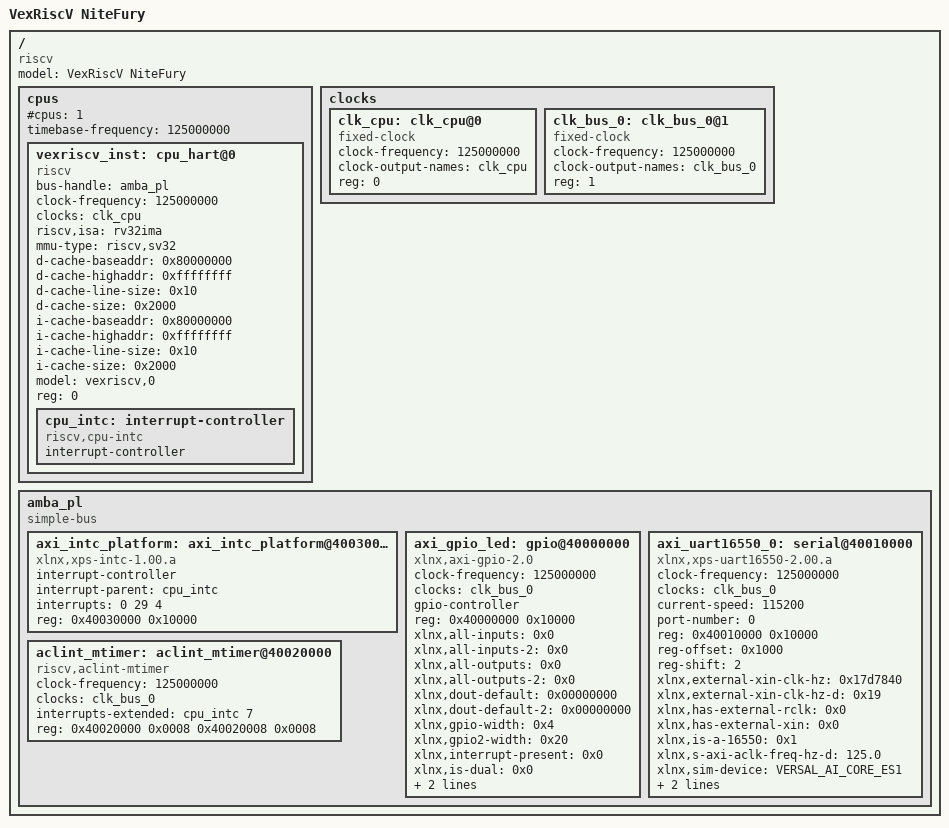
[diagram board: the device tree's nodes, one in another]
/*
 * CAUTION: This file is automatically generated by Xilinx.
 * Version: XSCT 2021.1
 * Today is: Sat Jan 15 06:48:48 2022
 */


/ {
	#address-cells = <1>;
	#size-cells = <1>;
	compatible = "riscv";
	model = "VexRiscV NiteFury";
	cpus {
		#address-cells = <1>;
		#cpus = <1>;
		#size-cells = <0>;
		timebase-frequency = <125000000>;

		vexriscv_inst: cpu_hart@0 {
			bus-handle = <&amba_pl>;
			clock-frequency = <125000000>;
			clocks = <&clk_cpu>;
			compatible = "riscv";
			riscv,isa = "rv32ima";
			mmu-type = "riscv,sv32";
			d-cache-baseaddr = <0x80000000>;
			d-cache-highaddr = <0xffffffff>;
			d-cache-line-size = <0x10>;
			d-cache-size = <0x2000>;
			device_type = "cpu";
			i-cache-baseaddr = <0x80000000>;
			i-cache-highaddr = <0xffffffff>;
			i-cache-line-size = <0x10>;
			i-cache-size = <0x2000>;
			//interrupt-handle = <&axi_intc_platform>;
			model = "vexriscv,0";
			reg = <0>;
			status = "okay";
			cpu_intc: interrupt-controller {
				compatible = "riscv,cpu-intc";
				#interrupt-cells = <1>;
				interrupt-controller;
			};
			// cpu_cycle_timer: cycle_timer {
			// 	clock-frequency = <125000000>;
			// 	compatible = "riscv,cycle-timer";
			// };
		};
	};
	clocks {
		#address-cells = <1>;
		#size-cells = <0>;
		clk_cpu: clk_cpu@0 {
			#clock-cells = <0>;
			clock-frequency = <125000000>;
			clock-output-names = "clk_cpu";
			compatible = "fixed-clock";
			reg = <0>;
		};
		clk_bus_0: clk_bus_0@1 {
			#clock-cells = <0>;
			clock-frequency = <125000000>;
			clock-output-names = "clk_bus_0";
			compatible = "fixed-clock";
			reg = <1>;
		};
	};
	amba_pl: amba_pl {
		#address-cells = <1>;
		#size-cells = <1>;
		compatible = "simple-bus";
		ranges ;
		axi_intc_platform: axi_intc_platform@40030000 {
			#interrupt-cells = <2>;
			compatible = "xlnx,xps-intc-1.00.a";
			interrupt-controller;
			interrupt-parent = <&cpu_intc>;
			interrupts = <0 29 4>;
			reg = <0x40030000 0x10000>;
		};
		axi_gpio_led: gpio@40000000 {
			#gpio-cells = <2>;
			clock-frequency = <125000000>;
			clock-names = "s_axi_aclk";
			clocks = <&clk_bus_0>;
			compatible = "xlnx,axi-gpio-2.0", "xlnx,xps-gpio-1.00.a";
			gpio-controller ;
			reg = <0x40000000 0x10000>;
			xlnx,all-inputs = <0x0>;
			xlnx,all-inputs-2 = <0x0>;
			xlnx,all-outputs = <0x0>;
			xlnx,all-outputs-2 = <0x0>;
			xlnx,dout-default = <0x00000000>;
			xlnx,dout-default-2 = <0x00000000>;
			xlnx,gpio-width = <0x4>;
			xlnx,gpio2-width = <0x20>;
			xlnx,interrupt-present = <0x0>;
			xlnx,is-dual = <0x0>;
			xlnx,tri-default = <0xFFFFFFFF>;
			xlnx,tri-default-2 = <0xFFFFFFFF>;
		};
		axi_uart16550_0: serial@40010000 {
			clock-frequency = <125000000>;
			clocks = <&clk_bus_0>;
			compatible = "xlnx,xps-uart16550-2.00.a", "ns16550a";
			current-speed = <115200>;
			device_type = "serial";
			// interrupt-names = "ip2intc_irpt";
			// interrupt-parent = <&axi_intc_platform>;
			// interrupts = <0 2>;
			port-number = <0>;
			reg = <0x40010000 0x10000>;
			reg-offset = <0x1000>;
			reg-shift = <2>;
			xlnx,external-xin-clk-hz = <0x17d7840>;
			xlnx,external-xin-clk-hz-d = <0x19>;
			xlnx,has-external-rclk = <0x0>;
			xlnx,has-external-xin = <0x0>;
			xlnx,is-a-16550 = <0x1>;
			xlnx,s-axi-aclk-freq-hz-d = "125.0";
			xlnx,sim-device = "VERSAL_AI_CORE_ES1";
			xlnx,use-modem-ports = <0x1>;
			xlnx,use-user-ports = <0x1>;
		};
		// axi_timer_0: timer@40020000 {
		// 	clock-frequency = <125000000>;
		// 	clocks = <&clk_bus_0>;
		// 	compatible = "xlnx,xps-timer-1.00.a";
		// 	interrupt-parent = <&axi_intc_platform>;
		// 	interrupts = <2 2>;
		// 	reg = <0x40020000 0x10000>;
		// 	xlnx,count-width = <0x20>;
		// 	xlnx,one-timer-only = <0x0>;
		// };
		aclint_mtimer: aclint_mtimer@40020000 {
			clock-frequency = <125000000>;
			clocks = <&clk_bus_0>;
			compatible = "riscv,aclint-mtimer";
			interrupts-extended = <&cpu_intc 7>;
			reg = <0x40020000 0x0008 0x40020008 0x0008>;
		};
	};
};
